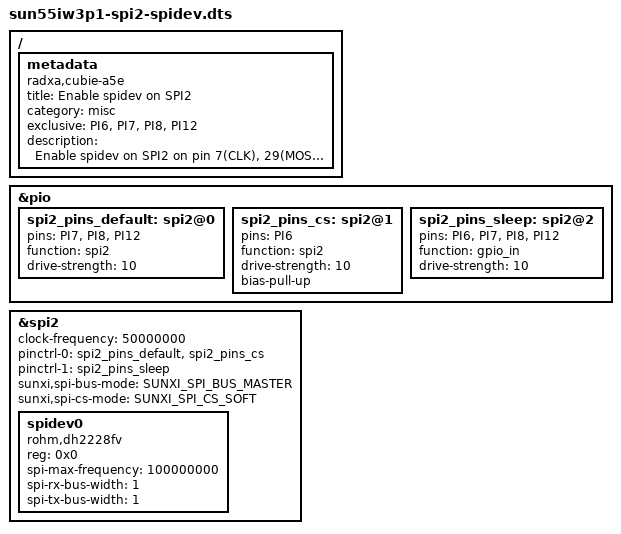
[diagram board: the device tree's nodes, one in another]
/dts-v1/;
/plugin/;
#include <dt-bindings/spi/sunxi-spi.h>

/{
	metadata {
		title = "Enable spidev on SPI2";
		compatible = "radxa,cubie-a5e";
		category = "misc";
		exclusive = "PI6", "PI7", "PI8", "PI12";
		description = "Enable spidev on SPI2 on
pin 7(CLK), 29(MOSI), 31(MISO), 33(CS0).";
	};
};

&pio {
	spi2_pins_default: spi2@0 {
		pins = "PI7", "PI8", "PI12";
		function = "spi2";
		drive-strength = <10>;
	};

	spi2_pins_cs: spi2@1 {
		pins = "PI6";
		function = "spi2";
		drive-strength = <10>;
		bias-pull-up; /* cs, hold, wp should be pulled up */
	};

	spi2_pins_sleep: spi2@2 {
		pins = "PI6", "PI7", "PI8", "PI12";
		function = "gpio_in";
		drive-strength = <10>;
	};
};

&spi2 {
	clock-frequency = <50000000>;
	pinctrl-0 = <&spi2_pins_default &spi2_pins_cs>;
	pinctrl-1 = <&spi2_pins_sleep>;
	pinctrl-names = "default", "sleep";
	sunxi,spi-bus-mode = <SUNXI_SPI_BUS_MASTER>;
	sunxi,spi-cs-mode = <SUNXI_SPI_CS_SOFT>;
	status = "okay";

	spidev0 {
		compatible = "rohm,dh2228fv";
		reg = <0x0>;
		spi-max-frequency = <100000000>;
		spi-rx-bus-width = <1>;
		spi-tx-bus-width = <1>;
		status = "okay";	
	};
};
